# ESP32-H2 register map
Vendor: ESPRESSIF SYSTEMS (SHANGHAI) CO., LTD.; Series: ESP32 H-Series; File version: 12
CPU: RV32IMAC r0p0, little endian, no MPU, no FPU, 0 interrupt priority bits
Address unit: 32 bits
Registers are 32-bit, read-write, reset 0x0 unless marked. A register's access mark holds for its fields unless they carry their own. Offsets are from the block's base; [hi:lo] are bit positions; {n}, {i} and the like mark numbered series.

## MODEM_SYSCON — MODEM_SYSCON Peripheral
Base 0x600A5400
0x00 TEST_CONF
  [0] CLK_EN
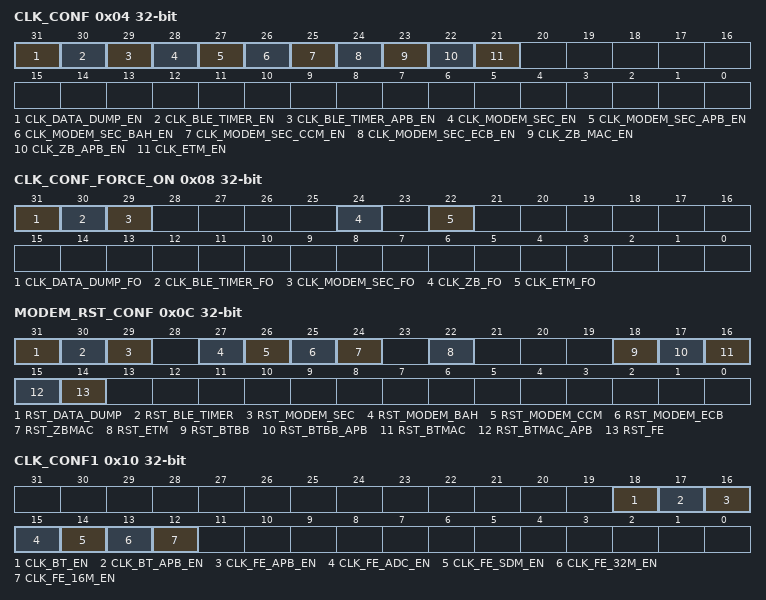
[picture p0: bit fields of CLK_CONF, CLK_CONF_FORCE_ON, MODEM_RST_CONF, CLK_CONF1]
0x04 CLK_CONF
  [31] CLK_DATA_DUMP_EN, [30] CLK_BLE_TIMER_EN, [29] CLK_BLE_TIMER_APB_EN, [28] CLK_MODEM_SEC_EN, [27] CLK_MODEM_SEC_APB_EN, [26] CLK_MODEM_SEC_BAH_EN, [25] CLK_MODEM_SEC_CCM_EN, [24] CLK_MODEM_SEC_ECB_EN, [23] CLK_ZB_MAC_EN, [22] CLK_ZB_APB_EN, [21] CLK_ETM_EN
0x08 CLK_CONF_FORCE_ON
  [31] CLK_DATA_DUMP_FO, [30] CLK_BLE_TIMER_FO, [29] CLK_MODEM_SEC_FO, [24] CLK_ZB_FO, [22] CLK_ETM_FO
0x0C MODEM_RST_CONF
  [31] RST_DATA_DUMP, [30] RST_BLE_TIMER, [29] RST_MODEM_SEC, [27] RST_MODEM_BAH, [26] RST_MODEM_CCM, [25] RST_MODEM_ECB, [24] RST_ZBMAC, [22] RST_ETM, [18] RST_BTBB, [17] RST_BTBB_APB, [16] RST_BTMAC, [15] RST_BTMAC_APB, [14] RST_FE
0x10 CLK_CONF1
  [18] CLK_BT_EN, [17] CLK_BT_APB_EN, [16] CLK_FE_APB_EN, [15] CLK_FE_ADC_EN, [14] CLK_FE_SDM_EN, [13] CLK_FE_32M_EN, [12] CLK_FE_16M_EN
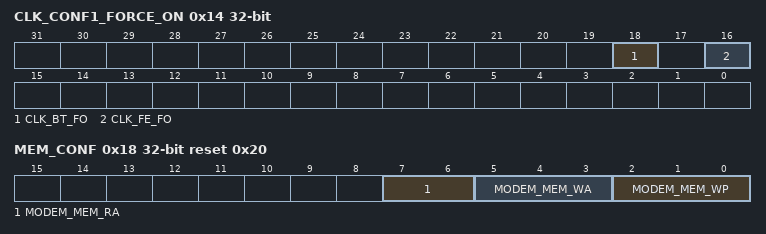
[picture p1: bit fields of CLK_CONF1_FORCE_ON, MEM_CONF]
0x14 CLK_CONF1_FORCE_ON
  [18] CLK_BT_FO, [16] CLK_FE_FO
0x18 MEM_CONF reset 0x20
  [7:6] MODEM_MEM_RA, [5:3] MODEM_MEM_WA, [2:0] MODEM_MEM_WP
0x1C DATE — Version control register

## OTP_DEBUG — OTP_DEBUG Peripheral
Base 0x600B3C00
0x00 WR_DIS ro — Otp debuger block0 data register1.
  [31:0] BLOCK0_WR_DIS — Otp block0 write disable data.
{0x0+4i} BLK0_BACKUP1_W{i} ro (i=1..5) — Otp debuger block0 data register{i+1}.
  [31:0] OTP_BEBUG_BLOCK0_BACKUP1_W{i} — Otp block0 backup1 word{i} data.
{0x14+4i} BLK0_BACKUP2_W{i} ro (i=1..5) — Otp debuger block0 data register{i+6}.
  [31:0] OTP_BEBUG_BLOCK0_BACKUP2_W{i} — Otp block0 backup2 word{i} data.
{0x28+4i} BLK0_BACKUP3_W{i} ro (i=1..5) — Otp debuger block0 data register{i+11}.
  [31:0] OTP_BEBUG_BLOCK0_BACKUP3_W{i} — Otp block0 backup3 word{i} data.
{0x3C+4i} BLK0_BACKUP4_W{i} ro (i=1..5) — Otp debuger block0 data register{i+16}.
  [31:0] OTP_BEBUG_BLOCK0_BACKUP4_W{i} — Otp block0 backup4 word{i} data.
{0x50+4i} BLK1_W{i} ro (i=1..9) — Otp debuger block1 data register{i}.
  [31:0] BLOCK1_W{i} — Otp block1 word{i} data.
{0x74+4i} BLK2_W{i} ro (i=1..11) — Otp debuger block2 data register{i}.
  [31:0] BLOCK2_W{i} — Otp block2 word{i} data.
{0xA0+4i} BLK3_W{i} ro (i=1..11) — Otp debuger block3 data register{i}.
  [31:0] BLOCK3_W{i} — Otp block3 word{i} data.
{0xCC+4i} BLK4_W{i} ro (i=1..9) — Otp debuger block4 data register{i}.
  [31:0] BLOCK4_W{i} — Otp block4 word{i} data.
0xF4 BLK4_W10 ro — Otp debuger block4 data registe10.
  [31:0] BLOCK4_W10 — Otp block4 word10 data.
0xF8 BLK4_W11 ro — Otp debuger block4 data register11.
  [31:0] BLOCK4_W11 — Otp block4 word11 data.
{0xF8+4i} BLK5_W{i} ro (i=1..11) — Otp debuger block5 data register{i}.
  [31:0] BLOCK5_W{i} — Otp block5 word{i} data.
{0x124+4i} BLK6_W{i} ro (i=1..11) — Otp debuger block6 data register{i}.
  [31:0] BLOCK6_W{i} — Otp block6 word{i} data.
{0x150+4i} BLK7_W{i} ro (i=1..11) — Otp debuger block7 data register{i}.
  [31:0] BLOCK7_W{i} — Otp block7 word{i} data.
{0x17C+4i} BLK8_W{i} ro (i=1..11) — Otp debuger block8 data register{i}.
  [31:0] BLOCK8_W{i} — Otp block8 word{i} data.
{0x1A8+4i} BLK9_W{i} ro (i=1..11) — Otp debuger block9 data register{i}.
  [31:0] BLOCK9_W{i} — Otp block9 word{i} data.
{0x1D4+4i} BLK10_W{i} ro (i=1..9) — Otp debuger block10 data register{i}.
  [31:0] BLOCK10_W{i} — Otp block10 word{i} data.
0x1FC BLK10_W10 ro — Otp debuger block10 data register10.
  [31:0] BLOCK19_W10 — Otp block10 word10 data.
0x200 BLK10_W11 ro — Otp debuger block10 data register11.
  [31:0] BLOCK10_W11 — Otp block10 word11 data.
0x204 CLK — Otp debuger clk_en configuration register.
  [0] EN — Force clock on for this register file.
0x208 APB2OTP_EN — Otp_debuger apb2otp enable configuration register.
  [0] APB2OTP_EN — Debug mode enable signal.
0x20C DATE — eFuse version register.
